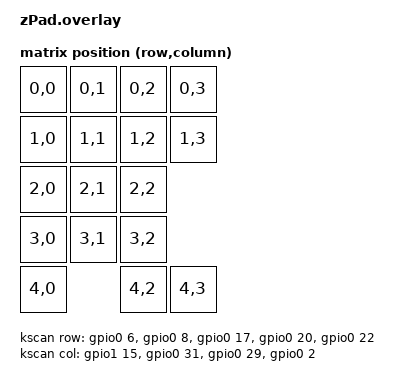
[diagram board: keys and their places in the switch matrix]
// This file was generated from a template. Edit it to match your keyboard.
// See https://zmk.dev/docs/development/hardware-integration/new-shield for more
// instructions.

#include <dt-bindings/zmk/matrix_transform.h>

#include "zPad-layouts.dtsi"

/ {
    chosen {
        zmk,physical-layout = &default_layout;
    };

    kscan: kscan {
        // If the hardware does not use a switch matrix, change this to the
        // appropriate driver and update the properties below to match.
        // See https://zmk.dev/docs/config/kscan for supported key scan drivers.
        compatible = "zmk,kscan-gpio-matrix";
        // Set this to "col2row" or "row2col" to match the hardware. If using
        // "row2col", change the col-gpios to (GPIO_ACTIVE_HIGH | GPIO_PULL_DOWN)
        // and the row-gpios to GPIO_ACTIVE_HIGH.
        diode-direction = "col2row";
        wakeup-source;

        // Replace these comments with the GPIO pins in the matrix.
        // See https://zmk.dev/docs/development/hardware-integration/new-shield#shield-overlays
        col-gpios
            =   <&gpio1 15 GPIO_ACTIVE_LOW>,
                <&gpio0 31 GPIO_ACTIVE_LOW>,
                <&gpio0 29 GPIO_ACTIVE_LOW>,
                <&gpio0 2  GPIO_ACTIVE_LOW>;

        row-gpios
            = <&gpio0 6 (GPIO_PULL_UP | GPIO_ACTIVE_LOW)>,
              <&gpio0 8 (GPIO_PULL_UP | GPIO_ACTIVE_LOW)>,
              <&gpio0 17 (GPIO_PULL_UP | GPIO_ACTIVE_LOW)>,
              <&gpio0 20 (GPIO_PULL_UP | GPIO_ACTIVE_LOW)>,
              <&gpio0 22 (GPIO_PULL_UP | GPIO_ACTIVE_LOW)>;
    };

    default_transform: default_transform {
        // See https://zmk.dev/docs/development/hardware-integration/new-shield#matrix-transform
        // for how to configure this
        compatible = "zmk,matrix-transform";
        columns = <5>;
        rows = <4>;

        map = <
            RC(0,0) RC(0,1) RC(0,2) RC(0,3)       // NUMLOCK, SLASH, ASTERISK, MINUS
            RC(1,0) RC(1,1) RC(1,2) RC(1,3)       // 9, 8, 7, +
            RC(2,0) RC(2,1) RC(2,2) RC_UNUSED     // PLUS, 6, 5
            RC(3,0) RC(3,1) RC(3,2) RC_UNUSED     // 3, 2, 1
            RC(4,0) RC_UNUSED RC(4,2) RC(4,3)     // ENTER, DOT, 0
        >;
    };
};
